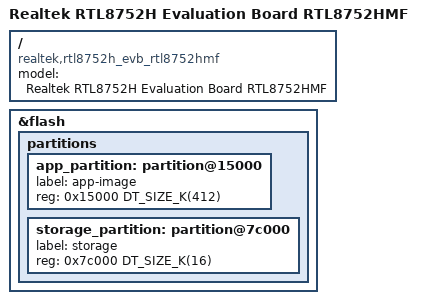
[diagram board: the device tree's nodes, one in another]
/*
 * Copyright (c) 2026, Realtek Semiconductor Corporation.
 *
 * SPDX-License-Identifier: Apache-2.0
 */

/dts-v1/;
#include <realtek/bee/rtl8752hmf.dtsi>
#include "rtl8752h_evb_common.dtsi"

/ {
	model = "Realtek RTL8752H Evaluation Board RTL8752HMF";
	compatible = "realtek,rtl8752h_evb_rtl8752hmf";
};

&flash {
	partitions {
		app_partition: partition@15000 {
			label = "app-image";
			reg = <0x15000 DT_SIZE_K(412)>;
		};

		storage_partition: partition@7c000 {
			label = "storage";
			reg = <0x7c000 DT_SIZE_K(16)>;
		};
	};
};
